VERSION ""

NS_ :

BS_:

BU_:

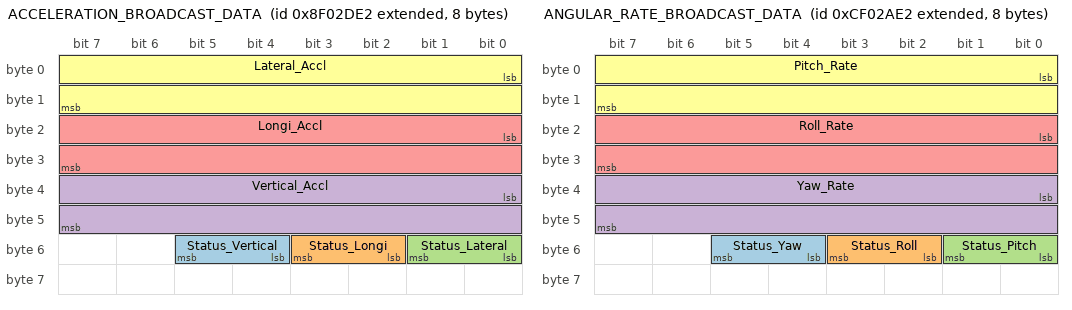
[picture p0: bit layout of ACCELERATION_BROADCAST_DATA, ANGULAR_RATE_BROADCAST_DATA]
BO_ 2297441762 ACCELERATION_BROADCAST_DATA: 8 Vector__XXX
 SG_ Status_Vertical : 52|2@1+ (1,0) [0|0] "" Vector__XXX
 SG_ Status_Longi : 50|2@1+ (1,0) [0|0] "" Vector__XXX
 SG_ Status_Lateral : 48|2@1+ (1,0) [0|0] "" Vector__XXX
 SG_ Vertical_Accl : 32|16@1+ (0.01,-320) [0|0] "m/s^2" Vector__XXX
 SG_ Longi_Accl : 16|16@1+ (0.01,-320) [0|0] "m/s^2" Vector__XXX
 SG_ Lateral_Accl : 0|16@1+ (0.01,-320) [0|0] "m/s^2" Vector__XXX

BO_ 2364549858 ANGULAR_RATE_BROADCAST_DATA: 8 Vector__XXX
 SG_ Status_Yaw : 52|2@1+ (1,0) [0|0] "" Vector__XXX
 SG_ Status_Roll : 50|2@1+ (1,0) [0|0] "" Vector__XXX
 SG_ Status_Pitch : 48|2@1+ (1,0) [0|0] "" Vector__XXX
 SG_ Yaw_Rate : 32|16@1+ (0.0078125,-250) [0|0] "deg/s" Vector__XXX
 SG_ Roll_Rate : 16|16@1+ (0.0078125,-250) [0|0] "deg/s" Vector__XXX
 SG_ Pitch_Rate : 0|16@1+ (0.0078125,-250) [0|0] "deg/s" Vector__XXX

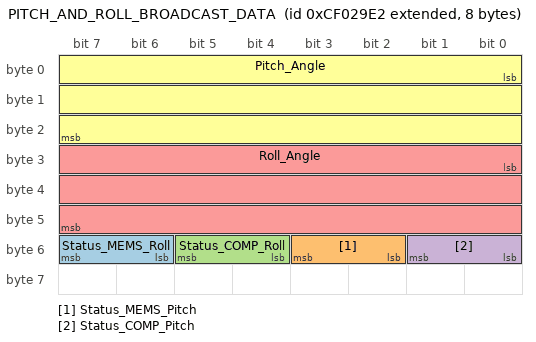
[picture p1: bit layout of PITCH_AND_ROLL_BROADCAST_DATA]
BO_ 2364549602 PITCH_AND_ROLL_BROADCAST_DATA: 8 Vector__XXX
 SG_ Status_MEMS_Roll : 54|2@1+ (1,0) [0|0] "" Vector__XXX
 SG_ Status_MEMS_Pitch : 50|2@1+ (1,0) [0|0] "" Vector__XXX
 SG_ Status_COMP_Roll : 52|2@1+ (1,0) [0|0] "" Vector__XXX
 SG_ Status_COMP_Pitch : 48|2@1+ (1,0) [0|0] "" Vector__XXX
 SG_ Roll_Angle : 24|24@1+ (3.0517578125E-005,-250) [0|0] "deg" Vector__XXX
 SG_ Pitch_Angle : 0|24@1+ (3.0517578125E-005,-250) [0|0] "deg" Vector__XXX

BA_DEF_ SG_  "SigType" ENUM  "Default","Range","RangeSigned","ASCII","Discrete","Control","ReferencePGN","DTC","StringDelimiter","StringLength","StringLengthControl","MessageCounter","MessageChecksum";
BA_DEF_ SG_  "GenSigEVName" STRING ;
BA_DEF_ SG_  "GenSigILSupport" ENUM  "No","Yes";
BA_DEF_ SG_  "GenSigSendType" ENUM  "Cyclic","OnWrite","OnWriteWithRepetition","OnChange","OnChangeWithRepetition","IfActive","IfActiveWithRepetition","NoSigSendType";
BA_DEF_ SG_  "GenSigStartValue" INT 0 2147483647;
BA_DEF_ BO_  "GenMsgILSupport" ENUM  "No","Yes";
BA_DEF_ BU_  "NmStationAddress" INT 0 255;
BA_DEF_ BO_  "GenMsgSendType" ENUM  "cyclic","NotUsed","IfActive","NotUsed","NotUsed","NotUsed","NotUsed","NotUsed","noMsgSendType";
BA_DEF_ BO_  "GenMsgRequestable" INT 0 1;
BA_DEF_  "DBName" STRING ;
BA_DEF_  "BusType" STRING ;
BA_DEF_  "ProtocolType" STRING ;
BA_DEF_ BO_  "VFrameFormat" ENUM  "StandardCAN","ExtendedCAN","reserved","J1939PG";
BA_DEF_DEF_  "SigType" "Default";
BA_DEF_DEF_  "GenSigEVName" "Env@Nodename_@Signame";
BA_DEF_DEF_  "GenSigILSupport" "Yes";
BA_DEF_DEF_  "GenSigSendType" "NoSigSendType";
BA_DEF_DEF_  "GenSigStartValue" 0;
BA_DEF_DEF_  "GenMsgILSupport" "Yes";
BA_DEF_DEF_  "NmStationAddress" 254;
BA_DEF_DEF_  "GenMsgSendType" "noMsgSendType";
BA_DEF_DEF_  "GenMsgRequestable" 1;
BA_DEF_DEF_  "DBName" "";
BA_DEF_DEF_  "BusType" "CAN";
BA_DEF_DEF_  "ProtocolType" "J1939";
BA_DEF_DEF_  "VFrameFormat" "J1939PG";
BA_ "DBName" "TARS_IMU_database";
BA_ "GenSigStartValue" SG_ 2297441762 Vertical_Accl 32000;
BA_ "GenSigStartValue" SG_ 2297441762 Longi_Accl 32000;
BA_ "GenSigStartValue" SG_ 2297441762 Lateral_Accl 32000;
BA_ "GenSigStartValue" SG_ 2364549858 Yaw_Rate 32000;
BA_ "GenSigStartValue" SG_ 2364549858 Roll_Rate 32000;
BA_ "GenSigStartValue" SG_ 2364549858 Pitch_Rate 32000;
BA_ "GenSigStartValue" SG_ 2364549602 Roll_Angle 8192000;
BA_ "GenSigStartValue" SG_ 2364549602 Pitch_Angle 8192000;
